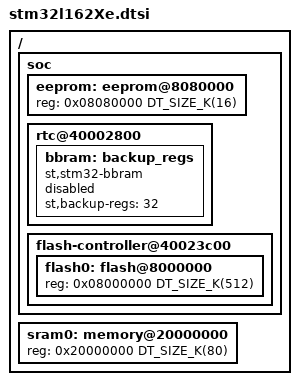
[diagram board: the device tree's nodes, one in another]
/*
 * Copyright (c) 2026 Filip Stojanovic <filipembedded@gmail.com>
 *
 * SPDX-License-Identifier: Apache-2.0
 */

#include <st/l1/stm32l162.dtsi>

/ {
	soc {
		eeprom: eeprom@8080000 {
			reg = <0x08080000 DT_SIZE_K(16)>;
		};

		rtc@40002800 {
			bbram: backup_regs {
				compatible = "st,stm32-bbram";
				st,backup-regs = <32>;
				status = "disabled";
			};
		};

		flash-controller@40023c00 {
			flash0: flash@8000000 {
				reg = <0x08000000 DT_SIZE_K(512)>;
				ranges = <0 0x8000000 DT_SIZE_K(512)>;
			};
		};
	};

	sram0: memory@20000000 {
		reg = <0x20000000 DT_SIZE_K(80)>;
	};
};
